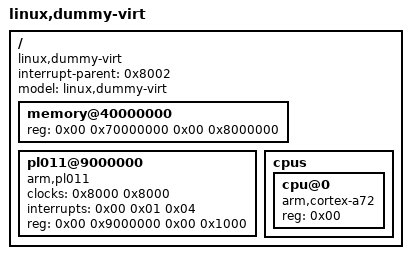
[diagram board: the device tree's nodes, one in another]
/dts-v1/;

/ {
	interrupt-parent = <0x8002>;
	model = "linux,dummy-virt";
	#size-cells = <0x02>;
	#address-cells = <0x02>;
	compatible = "linux,dummy-virt";

	memory@40000000 {
		reg = <0x00 0x70000000 0x00 0x8000000>;
		device_type = "memory";
	};

	pl011@9000000 {
		clock-names = "uartclk\0apb_pclk";
		clocks = <0x8000 0x8000>;
		interrupts = <0x00 0x01 0x04>;
		reg = <0x00 0x9000000 0x00 0x1000>;
		compatible = "arm,pl011\0arm,primecell";
	};

	cpus {
		#size-cells = <0x00>;
		#address-cells = <0x01>;
		cpu@0 {
			phandle = <0x8001>;
			reg = <0x00>;
			compatible = "arm,cortex-a72";
			device_type = "cpu";
		};
	};
};
